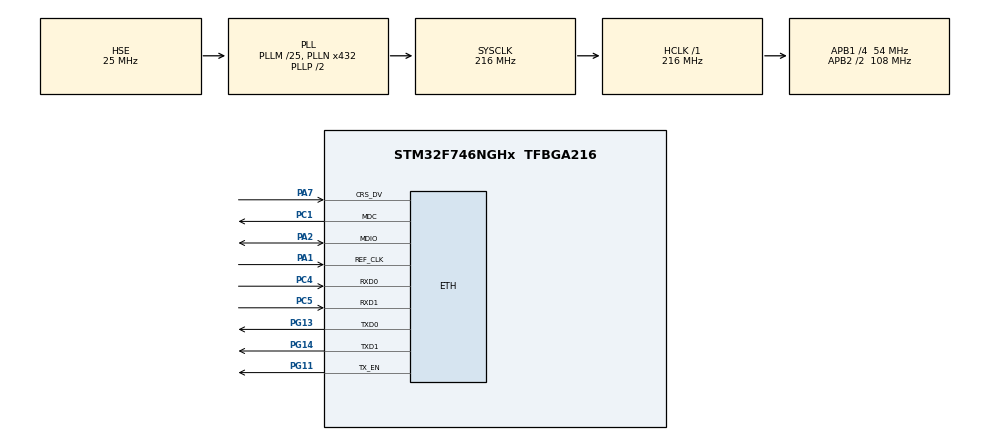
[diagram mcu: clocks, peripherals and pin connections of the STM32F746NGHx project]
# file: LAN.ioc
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CORTEX_M7.FlashInterface=AXI_Enabled
ETH.MediaInterface=ETH_MEDIA_INTERFACE_RMII
ETH.PHY_Name_RMII=LAN8742A_PHY_ADDRESS
ETH.PhyAddress=0
LWIP.CHECKSUM_BY_HARDWARE=1
LWIP.GATEWAY_ADDRESS=192.168.001.001
LWIP.IP_ADDRESS=192.168.001.099
LWIP.LWIP_DHCP=0
LWIP.LWIP_HTTPD=0
LWIP.MEMP_NUM_TCP_SEG=24
LWIP.NETMASK_ADDRESS=255.255.255.000
LWIP.Version=v2.0.3_Cube
Mcu.Family=STM32F7
Mcu.Name=STM32F746NGHx
Mcu.Package=TFBGA216
NVIC.PriorityGroup=NVIC_PRIORITYGROUP_4
PA1.Mode=RMII
PA1.Signal=ETH_REF_CLK
PA13.Mode=Serial_Wire
PA13.Signal=SYS_JTMS-SWDIO
PA14.Mode=Serial_Wire
PA14.Signal=SYS_JTCK-SWCLK
PA2.Mode=RMII
PA2.Signal=ETH_MDIO
PA7.Mode=RMII
PA7.Signal=ETH_CRS_DV
PC1.Mode=RMII
PC1.Signal=ETH_MDC
PC4.Mode=RMII
PC4.Signal=ETH_RXD0
PC5.Mode=RMII
PC5.Signal=ETH_RXD1
PG11.Mode=RMII
PG11.Signal=ETH_TX_EN
PG13.Mode=RMII
PG13.Signal=ETH_TXD0
PG14.Mode=RMII
PG14.Signal=ETH_TXD1
PH0/OSC_IN.Mode=HSE-External-Clock-Source
PH0/OSC_IN.Signal=RCC_OSC_IN
PH1/OSC_OUT.Mode=HSE-External-Clock-Source
PH1/OSC_OUT.Signal=RCC_OSC_OUT
ProjectManager.HeapSize=0x2000
ProjectManager.StackSize=0x4000
ProjectManager.TargetToolchain=MDK-ARM V5
RCC.AHBFreq_Value=216000000
RCC.APB1CLKDivider=RCC_HCLK_DIV4
RCC.APB1Freq_Value=54000000
RCC.APB1TimFreq_Value=108000000
RCC.APB2CLKDivider=RCC_HCLK_DIV2
RCC.APB2Freq_Value=108000000
RCC.APB2TimFreq_Value=216000000
RCC.CortexFreq_Value=216000000
RCC.EnbaleCSS=true
RCC.HCLKFreq_Value=216000000
RCC.HSE_VALUE=25000000
RCC.HSI_VALUE=16000000
RCC.LSE_VALUE=32768
RCC.PLLM=25
RCC.PLLN=432
RCC.PLLSourceVirtual=RCC_PLLSOURCE_HSE
RCC.SYSCLKFreq_VALUE=216000000
RCC.SYSCLKSource=RCC_SYSCLKSOURCE_PLLCLK
RCC.USBFreq_Value=216000000
RCC.VCOOutputFreq_Value=432000000
VP_LWIP_VS_Enabled.Mode=Enabled
board=LAN

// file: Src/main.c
/**
  ******************************************************************************
  * @file           : main.c
  * @brief          : Main program body
  ******************************************************************************
  * This notice applies to any and all portions of this file
  * that are not between comment pairs USER CODE BEGIN and
  * USER CODE END. Other portions of this file, whether
  * inserted by the user or by software development tools
  * are owned by their respective copyright owners.
  *
  * Copyright (c) 2018 STMicroelectronics International N.V.
  * All rights reserved.
  *
  * Redistribution and use in source and binary forms, with or without
  * modification, are permitted, provided that the following conditions are met:
  *
  * 1. Redistribution of source code must retain the above copyright notice,
  *    this list of conditions and the following disclaimer.
  * 2. Redistributions in binary form must reproduce the above copyright notice,
  *    this list of conditions and the following disclaimer in the documentation
  *    and/or other materials provided with the distribution.
  * 3. Neither the name of STMicroelectronics nor the names of other
  *    contributors to this software may be used to endorse or promote products
  *    derived from this software without specific written permission.
  * 4. This software, including modifications and/or derivative works of this
  *    software, must execute solely and exclusively on microcontroller or
  *    microprocessor devices manufactured by or for STMicroelectronics.
  * 5. Redistribution and use of this software other than as permitted under
  *    this license is void and will automatically terminate your rights under
  *    this license.
  *
  * THIS SOFTWARE IS PROVIDED BY STMICROELECTRONICS AND CONTRIBUTORS "AS IS"
  * AND ANY EXPRESS, IMPLIED OR STATUTORY WARRANTIES, INCLUDING, BUT NOT
  * LIMITED TO, THE IMPLIED WARRANTIES OF MERCHANTABILITY, FITNESS FOR A
  * PARTICULAR PURPOSE AND NON-INFRINGEMENT OF THIRD PARTY INTELLECTUAL PROPERTY
  * RIGHTS ARE DISCLAIMED TO THE FULLEST EXTENT PERMITTED BY LAW. IN NO EVENT
  * SHALL STMICROELECTRONICS OR CONTRIBUTORS BE LIABLE FOR ANY DIRECT, INDIRECT,
  * INCIDENTAL, SPECIAL, EXEMPLARY, OR CONSEQUENTIAL DAMAGES (INCLUDING, BUT NOT
  * LIMITED TO, PROCUREMENT OF SUBSTITUTE GOODS OR SERVICES; LOSS OF USE, DATA,
  * OR PROFITS; OR BUSINESS INTERRUPTION) HOWEVER CAUSED AND ON ANY THEORY OF
  * LIABILITY, WHETHER IN CONTRACT, STRICT LIABILITY, OR TORT (INCLUDING
  * NEGLIGENCE OR OTHERWISE) ARISING IN ANY WAY OUT OF THE USE OF THIS SOFTWARE,
  * EVEN IF ADVISED OF THE POSSIBILITY OF SUCH DAMAGE.
  *
  ******************************************************************************
  */
#include "main.h"
#include "stm32f7xx_hal.h"
#include "lwip.h"

/* USER CODE BEGIN Includes */
#include "udp_socket.h"

/* USER CODE END Includes */

/* USER CODE BEGIN PV */
/* Private variables ---------------------------------------------------------*/
char mass[] = "Hello from stm UDP \r\n";
/* USER CODE END PV */

void SystemClock_Config(void);
static void MX_GPIO_Init(void);

/* USER CODE BEGIN PFP */
/* Private function prototypes -----------------------------------------------*/

/* USER CODE END PFP */

int main(void)
{

  /* MCU Configuration----------------------------------------------------------*/

  /* Reset of all peripherals, Initializes the Flash interface and the Systick. */
  HAL_Init();

  /* Configure the system clock */
  SystemClock_Config();
	uint32_t WD_tick = HAL_GetTick();

  /* Initialize all configured peripherals */
  MX_GPIO_Init();
  MX_LWIP_Init();
  /* USER CODE BEGIN 2 */
	UDPTransportInit();

  /* USER CODE END 2 */

  /* Infinite loop */
  while (1)
  {

  /* USER CODE BEGIN 3 */
		MX_LWIP_Process();

		if((HAL_GetTick() - WD_tick) >= 1000)
			{
				UDPSend(mass,sizeof(mass));
				WD_tick = HAL_GetTick();
			}
  }
  /* USER CODE END 3 */

}

void SystemClock_Config(void)
{

  RCC_OscInitTypeDef RCC_OscInitStruct;
  RCC_ClkInitTypeDef RCC_ClkInitStruct;

    /**Configure the main internal regulator output voltage
    */
  __HAL_RCC_PWR_CLK_ENABLE();

  __HAL_PWR_VOLTAGESCALING_CONFIG(PWR_REGULATOR_VOLTAGE_SCALE1);

    /**Initializes the CPU, AHB and APB busses clocks
    */
  RCC_OscInitStruct.OscillatorType = RCC_OSCILLATORTYPE_HSE;
  RCC_OscInitStruct.HSEState = RCC_HSE_BYPASS;
  RCC_OscInitStruct.PLL.PLLState = RCC_PLL_ON;
  RCC_OscInitStruct.PLL.PLLSource = RCC_PLLSOURCE_HSE;
  RCC_OscInitStruct.PLL.PLLM = 25;
  RCC_OscInitStruct.PLL.PLLN = 432;
  RCC_OscInitStruct.PLL.PLLP = RCC_PLLP_DIV2;
  RCC_OscInitStruct.PLL.PLLQ = 2;
  if (HAL_RCC_OscConfig(&RCC_OscInitStruct) != HAL_OK)
  {
    _Error_Handler(__FILE__, __LINE__);
  }

    /**Activate the Over-Drive mode
    */
  if (HAL_PWREx_EnableOverDrive() != HAL_OK)
  {
    _Error_Handler(__FILE__, __LINE__);
  }

    /**Initializes the CPU, AHB and APB busses clocks
    */
  RCC_ClkInitStruct.ClockType = RCC_CLOCKTYPE_HCLK|RCC_CLOCKTYPE_SYSCLK
                              |RCC_CLOCKTYPE_PCLK1|RCC_CLOCKTYPE_PCLK2;
  RCC_ClkInitStruct.SYSCLKSource = RCC_SYSCLKSOURCE_PLLCLK;
  RCC_ClkInitStruct.AHBCLKDivider = RCC_SYSCLK_DIV1;
  RCC_ClkInitStruct.APB1CLKDivider = RCC_HCLK_DIV4;
  RCC_ClkInitStruct.APB2CLKDivider = RCC_HCLK_DIV2;

  if (HAL_RCC_ClockConfig(&RCC_ClkInitStruct, FLASH_LATENCY_7) != HAL_OK)
  {
    _Error_Handler(__FILE__, __LINE__);
  }

    /**Enables the Clock Security System
    */
  HAL_RCC_EnableCSS();

    /**Configure the Systick interrupt time
    */
  HAL_SYSTICK_Config(HAL_RCC_GetHCLKFreq()/1000);

    /**Configure the Systick
    */
  HAL_SYSTICK_CLKSourceConfig(SYSTICK_CLKSOURCE_HCLK);

  /* SysTick_IRQn interrupt configuration */
  HAL_NVIC_SetPriority(SysTick_IRQn, 0, 0);
}

/** Configure pins as
        * Analog
        * Input
        * Output
        * EVENT_OUT
        * EXTI
        * Free pins are configured automatically as Analog (this feature is enabled through
        * the Code Generation settings)
*/
static void MX_GPIO_Init(void)
{

  GPIO_InitTypeDef GPIO_InitStruct;

  /* GPIO Ports Clock Enable */
  __HAL_RCC_GPIOE_CLK_ENABLE();
  __HAL_RCC_GPIOG_CLK_ENABLE();
  __HAL_RCC_GPIOB_CLK_ENABLE();
  __HAL_RCC_GPIOD_CLK_ENABLE();
  __HAL_RCC_GPIOC_CLK_ENABLE();
  __HAL_RCC_GPIOA_CLK_ENABLE();
  __HAL_RCC_GPIOJ_CLK_ENABLE();
  __HAL_RCC_GPIOI_CLK_ENABLE();
  __HAL_RCC_GPIOK_CLK_ENABLE();
  __HAL_RCC_GPIOF_CLK_ENABLE();
  __HAL_RCC_GPIOH_CLK_ENABLE();

  /*Configure GPIO pins : PE4 PE3 PE2 PE1
                           PE0 PE5 PE6 PE8
                           PE9 PE11 PE14 PE7
                           PE10 PE12 PE15 PE13 */
  GPIO_InitStruct.Pin = GPIO_PIN_4|GPIO_PIN_3|GPIO_PIN_2|GPIO_PIN_1
                          |GPIO_PIN_0|GPIO_PIN_5|GPIO_PIN_6|GPIO_PIN_8
                          |GPIO_PIN_9|GPIO_PIN_11|GPIO_PIN_14|GPIO_PIN_7
                          |GPIO_PIN_10|GPIO_PIN_12|GPIO_PIN_15|GPIO_PIN_13;
  GPIO_InitStruct.Mode = GPIO_MODE_ANALOG;
  GPIO_InitStruct.Pull = GPIO_NOPULL;
  HAL_GPIO_Init(GPIOE, &GPIO_InitStruct);

  /*Configure GPIO pins : PB8 PB5 PB4 PB3
                           PB9 PB7 PB6 PB13
                           PB12 PB2 PB10 PB1
                           PB0 PB11 PB14 PB15 */
  GPIO_InitStruct.Pin = GPIO_PIN_8|GPIO_PIN_5|GPIO_PIN_4|GPIO_PIN_3
                          |GPIO_PIN_9|GPIO_PIN_7|GPIO_PIN_6|GPIO_PIN_13
                          |GPIO_PIN_12|GPIO_PIN_2|GPIO_PIN_10|GPIO_PIN_1
                          |GPIO_PIN_0|GPIO_PIN_11|GPIO_PIN_14|GPIO_PIN_15;
  GPIO_InitStruct.Mode = GPIO_MODE_ANALOG;
  GPIO_InitStruct.Pull = GPIO_NOPULL;
  HAL_GPIO_Init(GPIOB, &GPIO_InitStruct);

  /*Configure GPIO pins : PD7 PD6 PD0 PD5
                           PD3 PD1 PD4 PD2
                           PD15 PD10 PD14 PD9
                           PD8 PD12 PD13 PD11 */
  GPIO_InitStruct.Pin = GPIO_PIN_7|GPIO_PIN_6|GPIO_PIN_0|GPIO_PIN_5
                          |GPIO_PIN_3|GPIO_PIN_1|GPIO_PIN_4|GPIO_PIN_2
                          |GPIO_PIN_15|GPIO_PIN_10|GPIO_PIN_14|GPIO_PIN_9
                          |GPIO_PIN_8|GPIO_PIN_12|GPIO_PIN_13|GPIO_PIN_11;
  GPIO_InitStruct.Mode = GPIO_MODE_ANALOG;
  GPIO_InitStruct.Pull = GPIO_NOPULL;
  HAL_GPIO_Init(GPIOD, &GPIO_InitStruct);

  /*Configure GPIO pins : PC12 PC11 PC10 PC13
                           PC14 PC15 PC9 PC8
                           PC7 PC6 PC3 PC0
                           PC2 */
  GPIO_InitStruct.Pin = GPIO_PIN_12|GPIO_PIN_11|GPIO_PIN_10|GPIO_PIN_13
                          |GPIO_PIN_14|GPIO_PIN_15|GPIO_PIN_9|GPIO_PIN_8
                          |GPIO_PIN_7|GPIO_PIN_6|GPIO_PIN_3|GPIO_PIN_0
                          |GPIO_PIN_2;
  GPIO_InitStruct.Mode = GPIO_MODE_ANALOG;
  GPIO_InitStruct.Pull = GPIO_NOPULL;
  HAL_GPIO_Init(GPIOC, &GPIO_InitStruct);

  /*Configure GPIO pins : PA15 PA12 PA11 PA10
                           PA9 PA8 PA0 PA4
                           PA6 PA5 PA3 */
  GPIO_InitStruct.Pin = GPIO_PIN_15|GPIO_PIN_12|GPIO_PIN_11|GPIO_PIN_10
                          |GPIO_PIN_9|GPIO_PIN_8|GPIO_PIN_0|GPIO_PIN_4
                          |GPIO_PIN_6|GPIO_PIN_5|GPIO_PIN_3;
  GPIO_InitStruct.Mode = GPIO_MODE_ANALOG;
  GPIO_InitStruct.Pull = GPIO_NOPULL;
  HAL_GPIO_Init(GPIOA, &GPIO_InitStruct);

  /*Configure GPIO pins : PG15 PG12 PG10 PG9
                           PG8 PG7 PG6 PG1
                           PG3 PG2 PG0 PG5
                           PG4 */
  GPIO_InitStruct.Pin = GPIO_PIN_15|GPIO_PIN_12|GPIO_PIN_10|GPIO_PIN_9
                          |GPIO_PIN_8|GPIO_PIN_7|GPIO_PIN_6|GPIO_PIN_1
                          |GPIO_PIN_3|GPIO_PIN_2|GPIO_PIN_0|GPIO_PIN_5
                          |GPIO_PIN_4;
  GPIO_InitStruct.Mode = GPIO_MODE_ANALOG;
  GPIO_InitStruct.Pull = GPIO_NOPULL;
  HAL_GPIO_Init(GPIOG, &GPIO_InitStruct);

  /*Configure GPIO pins : PJ13 PJ12 PJ14 PJ15
                           PJ11 PJ8 PJ10 PJ7
                           PJ9 PJ6 PJ4 PJ5
                           PJ3 PJ2 PJ0 PJ1 */
  GPIO_InitStruct.Pin = GPIO_PIN_13|GPIO_PIN_12|GPIO_PIN_14|GPIO_PIN_15
                          |GPIO_PIN_11|GPIO_PIN_8|GPIO_PIN_10|GPIO_PIN_7
                          |GPIO_PIN_9|GPIO_PIN_6|GPIO_PIN_4|GPIO_PIN_5
                          |GPIO_PIN_3|GPIO_PIN_2|GPIO_PIN_0|GPIO_PIN_1;
  GPIO_InitStruct.Mode = GPIO_MODE_ANALOG;
  GPIO_InitStruct.Pull = GPIO_NOPULL;
  HAL_GPIO_Init(GPIOJ, &GPIO_InitStruct);

  /*Configure GPIO pins : PI8 PI4 PI3 PI2
                           PI5 PI7 PI10 PI6
                           PI1 PI12 PI9 PI0
                           PI11 PI13 PI15 PI14 */
  GPIO_InitStruct.Pin = GPIO_PIN_8|GPIO_PIN_4|GPIO_PIN_3|GPIO_PIN_2
                          |GPIO_PIN_5|GPIO_PIN_7|GPIO_PIN_10|GPIO_PIN_6
                          |GPIO_PIN_1|GPIO_PIN_12|GPIO_PIN_9|GPIO_PIN_0
                          |GPIO_PIN_11|GPIO_PIN_13|GPIO_PIN_15|GPIO_PIN_14;
  GPIO_InitStruct.Mode = GPIO_MODE_ANALOG;
  GPIO_InitStruct.Pull = GPIO_NOPULL;
  HAL_GPIO_Init(GPIOI, &GPIO_InitStruct);

  /*Configure GPIO pins : PK7 PK6 PK5 PK4
                           PK3 PK1 PK2 PK0 */
  GPIO_InitStruct.Pin = GPIO_PIN_7|GPIO_PIN_6|GPIO_PIN_5|GPIO_PIN_4
                          |GPIO_PIN_3|GPIO_PIN_1|GPIO_PIN_2|GPIO_PIN_0;
  GPIO_InitStruct.Mode = GPIO_MODE_ANALOG;
  GPIO_InitStruct.Pull = GPIO_NOPULL;
  HAL_GPIO_Init(GPIOK, &GPIO_InitStruct);

  /*Configure GPIO pins : PF0 PF1 PF2 PF3
                           PF4 PF7 PF6 PF5
                           PF10 PF9 PF8 PF12
                           PF15 PF13 PF14 PF11 */
  GPIO_InitStruct.Pin = GPIO_PIN_0|GPIO_PIN_1|GPIO_PIN_2|GPIO_PIN_3
                          |GPIO_PIN_4|GPIO_PIN_7|GPIO_PIN_6|GPIO_PIN_5
                          |GPIO_PIN_10|GPIO_PIN_9|GPIO_PIN_8|GPIO_PIN_12
                          |GPIO_PIN_15|GPIO_PIN_13|GPIO_PIN_14|GPIO_PIN_11;
  GPIO_InitStruct.Mode = GPIO_MODE_ANALOG;
  GPIO_InitStruct.Pull = GPIO_NOPULL;
  HAL_GPIO_Init(GPIOF, &GPIO_InitStruct);

  /*Configure GPIO pins : PH15 PH13 PH14 PH4
                           PH5 PH3 PH2 PH12
                           PH7 PH9 PH11 PH6
                           PH8 PH10 */
  GPIO_InitStruct.Pin = GPIO_PIN_15|GPIO_PIN_13|GPIO_PIN_14|GPIO_PIN_4
                          |GPIO_PIN_5|GPIO_PIN_3|GPIO_PIN_2|GPIO_PIN_12
                          |GPIO_PIN_7|GPIO_PIN_9|GPIO_PIN_11|GPIO_PIN_6
                          |GPIO_PIN_8|GPIO_PIN_10;
  GPIO_InitStruct.Mode = GPIO_MODE_ANALOG;
  GPIO_InitStruct.Pull = GPIO_NOPULL;
  HAL_GPIO_Init(GPIOH, &GPIO_InitStruct);

}

void _Error_Handler(char *file, int line)
{
  while(1)
  {
  }
}

/************************ (C) COPYRIGHT STMicroelectronics *****END OF FILE****/
